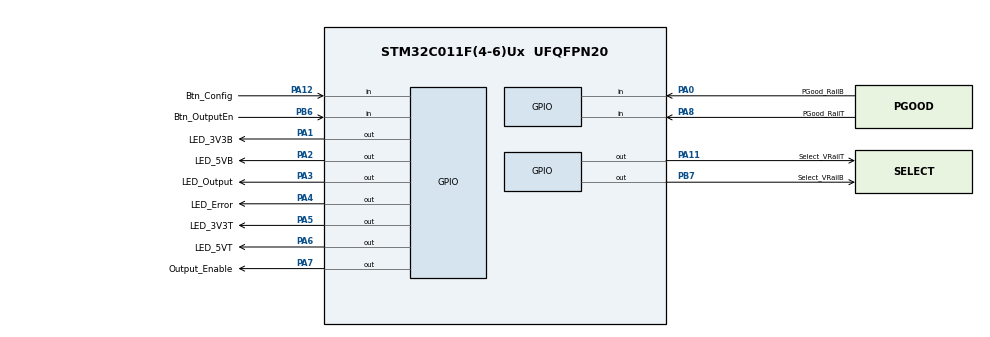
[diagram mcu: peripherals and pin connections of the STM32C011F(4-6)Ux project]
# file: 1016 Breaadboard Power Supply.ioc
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Mcu.Family=STM32C0
Mcu.Name=STM32C011F(4-6)Ux
Mcu.Package=UFQFPN20
NVIC.TIM3_IRQn=true\:0\:0\:false\:false\:true\:true\:true\:true
PA0.GPIO_Label=PGood_RailB
PA0.Signal=GPIO_Input
PA1.GPIO_Label=LED_3V3B
PA1.GPIO_ModeDefaultOutputPP=GPIO_MODE_OUTPUT_OD
PA1.GPIO_PuPd=GPIO_NOPULL
PA1.PinState=GPIO_PIN_SET
PA1.Signal=GPIO_Output
PA11\ [PA9].GPIO_Label=Select_VRailT
PA11\ [PA9].GPIO_ModeDefaultOutputPP=GPIO_MODE_OUTPUT_OD
PA11\ [PA9].GPIO_PuPd=GPIO_NOPULL
PA11\ [PA9].PinState=GPIO_PIN_SET
PA11\ [PA9].Signal=GPIO_Output
PA12\ [PA10].GPIO_Label=Btn_Config
PA12\ [PA10].GPIO_PuPd=GPIO_PULLUP
PA12\ [PA10].Signal=GPIO_Input
PA13.Mode=Serial_Wire
PA13.Signal=DEBUG_SWDIO
PA14-BOOT0.Mode=Serial_Wire
PA14-BOOT0.Signal=DEBUG_SWCLK
PA2.GPIO_Label=LED_5VB
PA2.GPIO_ModeDefaultOutputPP=GPIO_MODE_OUTPUT_OD
PA2.GPIO_PuPd=GPIO_NOPULL
PA2.PinState=GPIO_PIN_SET
PA2.Signal=GPIO_Output
PA3.GPIO_Label=LED_Output
PA3.GPIO_ModeDefaultOutputPP=GPIO_MODE_OUTPUT_OD
PA3.GPIO_PuPd=GPIO_NOPULL
PA3.PinState=GPIO_PIN_SET
PA3.Signal=GPIO_Output
PA4.GPIO_Label=LED_Error
PA4.GPIO_ModeDefaultOutputPP=GPIO_MODE_OUTPUT_OD
PA4.GPIO_PuPd=GPIO_NOPULL
PA4.PinState=GPIO_PIN_SET
PA4.Signal=GPIO_Output
PA5.GPIO_Label=LED_3V3T
PA5.GPIO_ModeDefaultOutputPP=GPIO_MODE_OUTPUT_OD
PA5.GPIO_PuPd=GPIO_NOPULL
PA5.PinState=GPIO_PIN_SET
PA5.Signal=GPIO_Output
PA6.GPIO_Label=LED_5VT
PA6.GPIO_ModeDefaultOutputPP=GPIO_MODE_OUTPUT_OD
PA6.GPIO_PuPd=GPIO_NOPULL
PA6.PinState=GPIO_PIN_SET
PA6.Signal=GPIO_Output
PA7.GPIO_Label=Output_Enable
PA7.Signal=GPIO_Output
PA8.GPIO_Label=PGood_RailT
PA8.Signal=GPIO_Input
PB6.GPIO_Label=Btn_OutputEn
PB6.GPIO_PuPd=GPIO_PULLUP
PB6.Signal=GPIO_Input
PB7.GPIO_Label=Select_VRailB
PB7.GPIO_ModeDefaultOutputPP=GPIO_MODE_OUTPUT_OD
PB7.GPIO_PuPd=GPIO_NOPULL
PB7.PinState=GPIO_PIN_SET
PB7.Signal=GPIO_Output
ProjectManager.HeapSize=0x200
ProjectManager.StackSize=0x400
ProjectManager.TargetToolchain=STM32CubeIDE
RCC.ADCFreq_Value=12000000
RCC.AHBCLKDivider=RCC_HCLK_DIV8
RCC.AHBFreq_Value=1500000
RCC.CortexFreq_Value=1500000
RCC.EXTERNAL_CLOCK_VALUE=12288000
RCC.HCLKFreq_Value=1500000
RCC.HSE_VALUE=8000000
RCC.HSI_VALUE=48000000
RCC.LSE_VALUE=32768
RCC.SYSCLKFreq_VALUE=12000000
TIM3.AutoReloadPreload=TIM_AUTORELOAD_PRELOAD_ENABLE
TIM3.Period=15000-1
VP_TIM3_VS_ClockSourceINT.Mode=Internal
board=custom

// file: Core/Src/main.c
/* USER CODE BEGIN Header */
/**
  ******************************************************************************
  * @file           : main.c
  * @brief          : Main program body
  ******************************************************************************
  * @attention
  *
  * Copyright (c) 2023 STMicroelectronics.
  * All rights reserved.
  *
  * This software is licensed under terms that can be found in the LICENSE file
  * in the root directory of this software component.
  * If no LICENSE file comes with this software, it is provided AS-IS.
  *
  ******************************************************************************
  */
/* USER CODE END Header */
#include "main.h"

/* USER CODE BEGIN Includes */
#include "1016top.h"
/* USER CODE END Includes */

TIM_HandleTypeDef htim3;

void SystemClock_Config(void);
static void MX_GPIO_Init(void);
static void MX_TIM3_Init(void);

int main(void)
{

  /* MCU Configuration--------------------------------------------------------*/

  /* Reset of all peripherals, Initializes the Flash interface and the Systick. */
  HAL_Init();

  /* Configure the system clock */
  SystemClock_Config();

  /* Initialize all configured peripherals */
  MX_GPIO_Init();
  MX_TIM3_Init();
  /* USER CODE BEGIN 2 */

  _1016_TimerSetup();

  /* USER CODE END 2 */

  /* Infinite loop */
  while (1)
  {

  }
}

void SystemClock_Config(void)
{
  RCC_OscInitTypeDef RCC_OscInitStruct = {0};
  RCC_ClkInitTypeDef RCC_ClkInitStruct = {0};

  /** Initializes the RCC Oscillators according to the specified parameters
  * in the RCC_OscInitTypeDef structure.
  */
  RCC_OscInitStruct.OscillatorType = RCC_OSCILLATORTYPE_HSI;
  RCC_OscInitStruct.HSIState = RCC_HSI_ON;
  RCC_OscInitStruct.HSIDiv = RCC_HSI_DIV4;
  RCC_OscInitStruct.HSICalibrationValue = RCC_HSICALIBRATION_DEFAULT;
  if (HAL_RCC_OscConfig(&RCC_OscInitStruct) != HAL_OK)
  {
    Error_Handler();
  }

  /** Initializes the CPU, AHB and APB buses clocks
  */
  RCC_ClkInitStruct.ClockType = RCC_CLOCKTYPE_HCLK|RCC_CLOCKTYPE_SYSCLK
                              |RCC_CLOCKTYPE_PCLK1;
  RCC_ClkInitStruct.SYSCLKSource = RCC_SYSCLKSOURCE_HSI;
  RCC_ClkInitStruct.SYSCLKDivider = RCC_SYSCLK_DIV1;
  RCC_ClkInitStruct.AHBCLKDivider = RCC_HCLK_DIV8;
  RCC_ClkInitStruct.APB1CLKDivider = RCC_APB1_DIV1;

  if (HAL_RCC_ClockConfig(&RCC_ClkInitStruct, FLASH_LATENCY_0) != HAL_OK)
  {
    Error_Handler();
  }
}

static void MX_TIM3_Init(void)
{

  TIM_ClockConfigTypeDef sClockSourceConfig = {0};
  TIM_MasterConfigTypeDef sMasterConfig = {0};

  htim3.Instance = TIM3;
  htim3.Init.Prescaler = 0;
  htim3.Init.CounterMode = TIM_COUNTERMODE_UP;
  htim3.Init.Period = 15000-1;
  htim3.Init.ClockDivision = TIM_CLOCKDIVISION_DIV1;
  htim3.Init.AutoReloadPreload = TIM_AUTORELOAD_PRELOAD_ENABLE;
  if (HAL_TIM_Base_Init(&htim3) != HAL_OK)
  {
    Error_Handler();
  }
  sClockSourceConfig.ClockSource = TIM_CLOCKSOURCE_INTERNAL;
  if (HAL_TIM_ConfigClockSource(&htim3, &sClockSourceConfig) != HAL_OK)
  {
    Error_Handler();
  }
  sMasterConfig.MasterOutputTrigger = TIM_TRGO_RESET;
  sMasterConfig.MasterSlaveMode = TIM_MASTERSLAVEMODE_DISABLE;
  if (HAL_TIMEx_MasterConfigSynchronization(&htim3, &sMasterConfig) != HAL_OK)
  {
    Error_Handler();
  }

}

static void MX_GPIO_Init(void)
{
  GPIO_InitTypeDef GPIO_InitStruct = {0};

  /* GPIO Ports Clock Enable */
  __HAL_RCC_GPIOA_CLK_ENABLE();
  __HAL_RCC_GPIOB_CLK_ENABLE();

  /*Configure GPIO pin Output Level */
  HAL_GPIO_WritePin(GPIOA, LED_3V3B_Pin|LED_5VB_Pin|LED_Output_Pin|LED_Error_Pin
                          |LED_3V3T_Pin|LED_5VT_Pin|Select_VRailT_Pin, GPIO_PIN_SET);

  /*Configure GPIO pin Output Level */
  HAL_GPIO_WritePin(Output_Enable_GPIO_Port, Output_Enable_Pin, GPIO_PIN_RESET);

  /*Configure GPIO pin Output Level */
  HAL_GPIO_WritePin(Select_VRailB_GPIO_Port, Select_VRailB_Pin, GPIO_PIN_SET);

  /*Configure GPIO pins : PGood_RailB_Pin PGood_RailT_Pin */
  GPIO_InitStruct.Pin = PGood_RailB_Pin|PGood_RailT_Pin;
  GPIO_InitStruct.Mode = GPIO_MODE_INPUT;
  GPIO_InitStruct.Pull = GPIO_NOPULL;
  HAL_GPIO_Init(GPIOA, &GPIO_InitStruct);

  /*Configure GPIO pins : LED_3V3B_Pin LED_5VB_Pin LED_Output_Pin LED_Error_Pin
                           LED_3V3T_Pin LED_5VT_Pin Select_VRailT_Pin */
  GPIO_InitStruct.Pin = LED_3V3B_Pin|LED_5VB_Pin|LED_Output_Pin|LED_Error_Pin
                          |LED_3V3T_Pin|LED_5VT_Pin|Select_VRailT_Pin;
  GPIO_InitStruct.Mode = GPIO_MODE_OUTPUT_OD;
  GPIO_InitStruct.Pull = GPIO_NOPULL;
  GPIO_InitStruct.Speed = GPIO_SPEED_FREQ_LOW;
  HAL_GPIO_Init(GPIOA, &GPIO_InitStruct);

  /*Configure GPIO pin : Output_Enable_Pin */
  GPIO_InitStruct.Pin = Output_Enable_Pin;
  GPIO_InitStruct.Mode = GPIO_MODE_OUTPUT_PP;
  GPIO_InitStruct.Pull = GPIO_NOPULL;
  GPIO_InitStruct.Speed = GPIO_SPEED_FREQ_LOW;
  HAL_GPIO_Init(Output_Enable_GPIO_Port, &GPIO_InitStruct);

  /*Configure GPIO pin : Btn_Config_Pin */
  GPIO_InitStruct.Pin = Btn_Config_Pin;
  GPIO_InitStruct.Mode = GPIO_MODE_INPUT;
  GPIO_InitStruct.Pull = GPIO_PULLUP;
  HAL_GPIO_Init(Btn_Config_GPIO_Port, &GPIO_InitStruct);

  /*Configure GPIO pin : Btn_OutputEn_Pin */
  GPIO_InitStruct.Pin = Btn_OutputEn_Pin;
  GPIO_InitStruct.Mode = GPIO_MODE_INPUT;
  GPIO_InitStruct.Pull = GPIO_PULLUP;
  HAL_GPIO_Init(Btn_OutputEn_GPIO_Port, &GPIO_InitStruct);

  /*Configure GPIO pin : Select_VRailB_Pin */
  GPIO_InitStruct.Pin = Select_VRailB_Pin;
  GPIO_InitStruct.Mode = GPIO_MODE_OUTPUT_OD;
  GPIO_InitStruct.Pull = GPIO_NOPULL;
  GPIO_InitStruct.Speed = GPIO_SPEED_FREQ_LOW;
  HAL_GPIO_Init(Select_VRailB_GPIO_Port, &GPIO_InitStruct);

}

void Error_Handler(void)
{
  __disable_irq();
  while (1)
  {
  }
}
